# NUC121AE_v1 register map
File version: 1.0
Registers are 32-bit, read-write, reset 0x0 unless marked. A register's access mark holds for its fields unless they carry their own. Offsets are from the block's base; [hi:lo] are bit positions; {n}, {i} and the like mark numbered series; 'fields as' and 'values as' point back to an identical list.

## ADC — ADC Register Map
Base 0x400E0000
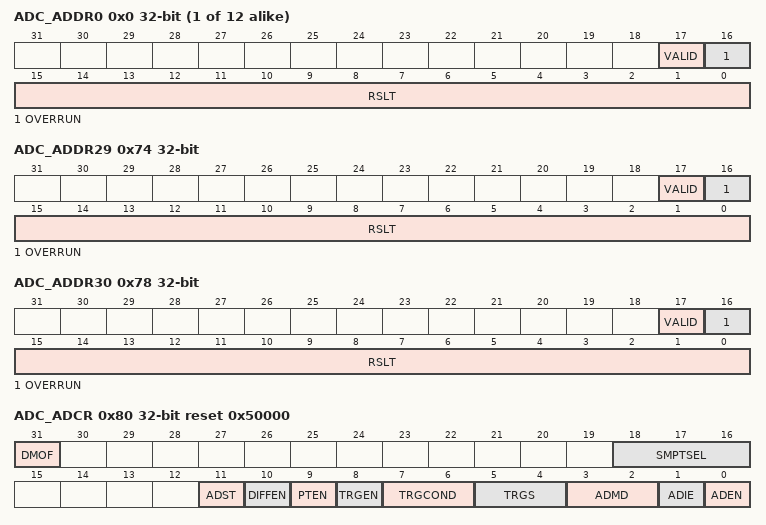
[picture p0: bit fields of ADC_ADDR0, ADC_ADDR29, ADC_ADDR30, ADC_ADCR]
{0x0+4i} ADC_ADDR{i} ro (i=0..11) — ADC Data Register {i}
  [17] VALID — Valid Flag. This bit will be set to 1 when the conversion of the corresponding channel is completed. This bit will be cleared to 0 by hardware after ADDR register is read
    0=Data in RSLT bits is not valid; 1=Data in RSLT bits is valid
  [16] OVERRUN — Overrun Flag. If converted data in RSLT has not been read before new conversion result is loaded to this register, OVERRUN is set to 1. It is cleared by hardware after ADDR register is read
    0=Data in RSLT is not overwrote; 1=Data in RSLT is overwrote
  [15:0] RSLT — A/D Conversion Result. This field contains conversion result of ADC.
0x74 ADC_ADDR29 ro — ADC Data Register 29
  fields as ADC_ADDR0
0x78 ADC_ADDR30 ro — ADC Data Register 30
  fields as ADC_ADDR0
0x80 ADC_ADCR reset 0x50000 — ADC Control Register
  [31] DMOF — Differential Input Mode Output Format. If user enables differential input mode, the conversion result can be expressed with binary straight format (unsigned format) or 2's complement format (signed format).
    0=A/D Conversion result will be filled in RSLT at ADDRx registers with unsigned format (straight binary format); 1=A/D Conversion result will be filled in RSLT at ADDRx registers with 2's complement format
  [18:16] SMPTSEL — ADC Internal Sampling Time Selection
    {v}={v+2} ADC clock for sampling ; {v+14} ADC clock for complete conversion (v=0..7)
  [11] ADST — A/D Conversion Start. ADST bit can be set to 1 from four sources: software, external pin STADC, PWM trigger and Timer trigger. ADST will be cleared to 0 by hardware automatically at the ends of Single mode and Single-cycle Scan mode. In Continuous Scan mode and Burst mode, A/D conversion is continuously performed until software writes 0 to this bit or chip is reset.
    0=Conversion stops and A/D converter enters idle state; 1=Conversion starts
  [10] DIFFEN — Differential Input Mode Control. Note: In Differential Input mode, only the even number of the two corresponding channels needs to be enabled in ADCHER register. The conversion result will be placed to the corresponding data register of the enabled channel.
    0=Single-end analog input mode; 1=Differential analog input mode
  [9] PTEN — PDMA Transfer Enable Bit. When A/D conversion is completed, the converted data is loaded into ADDR0~11, ADDR29~ADDR30. Software can enable this bit to generate a PDMA data transfer request.
    0=PDMA data transfer Disabled; 1=PDMA data transfer in ADDR0~11, ADDR29~ADDR30 Enabled
  [8] TRGEN — External Trigger Enable Control. Enable or disable triggering of A/D conversion by external STADC pin, PWM trigger and Timer trigger. If external trigger is enabled, the ADST bit can be set to 1 by the selected hardware trigger source. Note: The ADC external trigger function is only supported in Single-cycle Scan mode.
    0=External trigger Disabled; 1=External trigger Enabled
  [7:6] TRGCOND — External Trigger Condition. These two bits decide external pin STADC trigger event is level or edge. The signal must be kept at stable state at least 8 PCLKs for level trigger and at least 4 PCLKs for edge trigger.
    0=Low level; 1=High level; 2=Falling edge; 3=Rising edge
  [5:4] TRGS — Hardware Trigger Source. Note: Software should clear TRGEN bit and ADST bit to 0 before changing TRGS.
    0=A/D conversion is started by external STADC pin; 1=Timer0 ~ Timer3 overflow pulse trigger; 3=A/D conversion is started by PWM trigger
  [3:2] ADMD — A/D Converter Operation Mode Control. Note1: When changing the operation mode, software should clear ADST bit first. Note2: In Burst mode, the A/D result data always at Data Register 0.
    0=Single conversion; 1=Burst conversion; 2=Single-cycle Scan; 3=Continuous Scan
  [1] ADIE — A/D Interrupt Enable Control. A/D conversion end interrupt request is generated if ADIE bit is set to 1.
    0=A/D interrupt function Disabled; 1=A/D interrupt function Enabled
  [0] ADEN — A/D Converter Enable Bit. Note: Before starting A/D conversion function, this bit should be set to 1. Clear it to 0 to disable A/D converter analog circuit to save power consumption.
    0=A/D converter Disabled; 1=A/D converter Enabled
0x84 ADC_ADCHER — ADC Channel Enable Register
  [31:0] CHEN — Analog Input Channel Enable Control. Set CHEN[11:0] to enable the corresponding analog input channel 11 ~ 0. If DIFFEN bit is set to 1, only the even number channel needs to be enabled. Besides, set CHEN[29] to CHEN[30] will enable internal channel for band-gap voltage and temperature sensor respectively. Other bits are reserved. Note 1 : If the internal channel for band-gap voltage (CHEN[29]) is active, the maximum sampling rate will be TBD SPS. Note 2 : If the internal channel for temperature sensor (CHEN[30]) is active, the maximum sampling rate will be 300k SPS
    0=Channel Disabled; 1=Channel Enabled
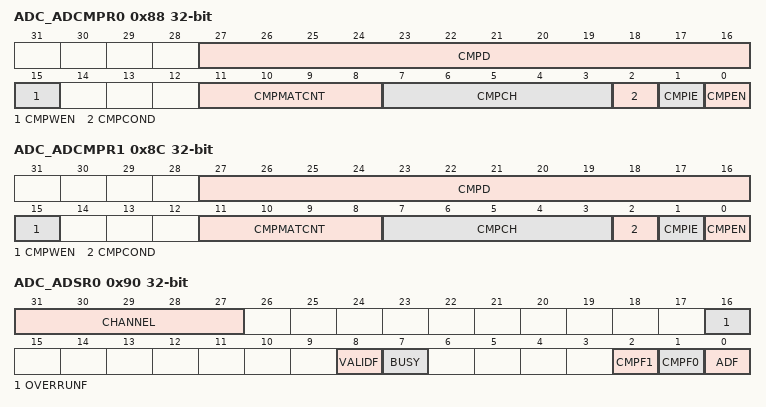
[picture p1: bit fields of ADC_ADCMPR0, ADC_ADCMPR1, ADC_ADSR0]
0x88 ADC_ADCMPR0 — ADC Compare Register 0
  [27:16] CMPD — Comparison Data. The 12-bit data is used to compare with conversion result of specified channel. Note: CMPD should be filled in unsigned format (straight binary format).
  [15] CMPWEN — Compare Window Mode Enable Bit. Note: This bit is only presented in ADCMPR0 register.
    0=Compare Window Mode Disabled; 1=Compare Window Mode Enabled
  [11:8] CMPMATCNT — Compare Match Count. When the specified A/D channel analog conversion result matches the compare condition defined by CMPCOND, the internal match counter will increase 1, otherwise, the internal match counter will be cleared to 0. When the internal counter reaches the value to (CMPMATCNT +1), the CMPFx bit will be set.
  [7:3] CMPCH — Compare Channel Selection
    {v}=Channel {v} conversion result is selected to be compared (v=0..11); 29=Band-gap voltage conversion result is selected to be compared; 30=Temperature sensor conversion result is selected to be compared
  [2] CMPCOND — Compare Condition. Note: When the compare result meets the condition setting, the internal match counter will increase 1, otherwise, the internal match counter will be cleared to 0. Note: When the internal counter reaches to (CMPMATCNT +1), the CMPFx bit will be set.
    0=Set the compare condition as that when a 12-bit A/D conversion result is less than the 12-bit CMPD (ADCMPRx[27:16]), the internal match counter will increase one; 1=Set the compare condition as that when a 12-bit A/D conversion result is greater than or equal to the 12-bit CMPD (ADCMPRx[27:16]), the internal match counter will increase one
  [1] CMPIE — Compare Interrupt Enable Control Bit. If the compare function is enabled and the compare condition matches the setting of CMPCOND and CMPMATCNT, CMPFx bit will be asserted, in the meanwhile, if CMPIE is set to 1, a compare interrupt request is generated.
    0=Compare function interrupt Disabled; 1=Compare function interrupt Enabled
  [0] CMPEN — Compare Enable Control Bit. Set this bit to 1 to enable ADC controller to compare CMPD[11:0] with specified channel conversion result when converted data is loaded into ADDR register.
    0=Compare function Disabled; 1=Compare function Enabled
0x8C ADC_ADCMPR1 — ADC Compare Register 1
  fields as ADC_ADCMPR0
0x90 ADC_ADSR0 — ADC Status Register0
  [31:27] CHANNEL — Current Conversion Channel. It is read only.
  [16] OVERRUNF — Overrun Flag. If any one of OVERRUN (ADDRx[16]) is set, this flag will be set to 1. This is a read only bit. Note: When ADC is in burst mode and the FIFO is overrun, this flag will be set to 1.
  [8] VALIDF — Data Valid Flag. If any one of VALID (ADDRx[17]) is set, this flag will be set to 1. This is a read only bit. Note: When ADC is in burst mode and any conversion result is valid, this flag will be set to 1
  [7] BUSY — BUSY/IDLE. This bit is a mirror of ADST bit in ADCR register. It is read only.
    0=A/D converter is in idle state; 1=A/D converter is busy at conversion
  [2] CMPF1 — Compare Flag 1. When the A/D conversion result of the selected channel meets setting condition in ADCMPR1 then this bit is set to 1; it is cleared by writing 1 to it
    0=Conversion result in ADDR does not meet ADCMPR1 setting; 1=Conversion result in ADDR meets ADCMPR1 setting
  [1] CMPF0 — Compare Flag 0. When the A/D conversion result of the selected channel meets setting condition in ADCMPR0 then this bit is set to 1. This bit is cleared by writing 1 to it.
    0=Conversion result in ADDR does not meet ADCMPR0 setting; 1=Conversion result in ADDR meets ADCMPR0 setting
  [0] ADF — A/D Conversion End Flag. A status flag that indicates the end of A/D conversion. Software can write 1 to clear this bit. ADF is set to 1 at the following three conditions: When A/D conversion ends in Single mode. When A/D conversion ends on all specified channels in Single-cycle Scan mode and Continuous Scan mode. When more than 8 samples in FIFO in Burst mode.
0x94 ADC_ADSR1 ro — ADC Status Register1
  [31:0] VALID — Data Valid Flag. VALID[30:29, 11:0] are the mirror of the VALID bits in ADDR30[17] ~ ADDR29[17], ADDR11[17]~ ADDR0[17]. The other bits are reserved. Note: When ADC is in burst mode and any conversion result is valid, VALID[30:29, 11:0] will be set to 1.
0x98 ADC_ADSR2 ro — ADC Status Register2
  [31:0] OVERRUN — Overrun Flag. OVERRUN[30:29, 11:0] are the mirror of the OVERRUN bit in ADDR30[16] ~ADDR29[16], ADDR11[16] ~ ADDR0[16]. The other bits are reserved. Note: When ADC is in burst mode and the FIFO is overrun, OVERRUN[30:29, 11:0] will be set to 1.
0x9C ADC_ADTDCR — ADC Trigger Delay Control Register
  [7:0] PTDT — PWM Trigger Delay Time. Set this field will delay ADC start conversion time after PWM trigger. PWM trigger delay time is (4 * PTDT) * system clock
0x100 ADC_ADPDMA ro — ADC PDMA Current Transfer Data Register
  [17:0] CURDAT — ADC PDMA Current Transfer Data Register. When PDMA transferring, read this register can monitor current PDMA transfer data. Current PDMA transfer data could be the content of ADDR0 ~ ADDR11 and ADDR29 ~ ADDR30. This is a read only register.
